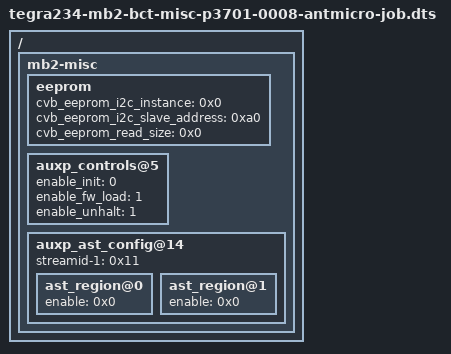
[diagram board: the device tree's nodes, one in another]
/dts-v1/;

#include "tegra234-mb2-bct-common.dtsi"

/ {
    mb2-misc {
		eeprom {
			cvb_eeprom_i2c_instance = <0x0>;
			cvb_eeprom_i2c_slave_address = <0xa0>;
			cvb_eeprom_read_size = <0x0>;
		};

		/* Control fields for FSI cluster. */
		auxp_controls@5 {
			enable_init = <0>;
			enable_fw_load = <1>;
			enable_unhalt = <1>;
		};

		/* Override Configuration fields for FSI CHSM AST. */
		auxp_ast_config@14 {
			streamid-1 = <0x11>;
			ast_region@0 {
				enable = <0x0>;
			};
			ast_region@1 {
				enable = <0x0>;
			};
		};
    };
};
